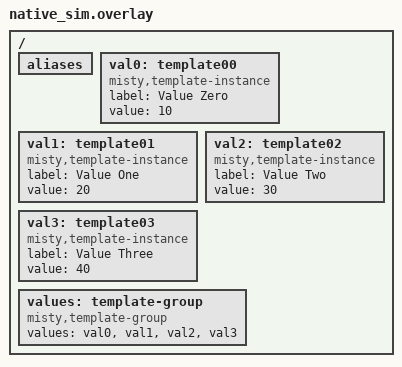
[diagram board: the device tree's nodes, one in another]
/**
 * @file native_sim.overlay
 * @date 20250526
 * @author flynnty
 * @copyright flynnty 2025
 *
 * @brief
 * Sim Overlay
 *
 */

/ {
	aliases {
	};

	val0: template00 {
		compatible = "misty,template-instance";
		#value-cells = <0>;
		label = "Value Zero";
		value = <10>;
	};

	val1: template01 {
		compatible = "misty,template-instance";
		#value-cells = <0>;
		label = "Value One";
		value = <20>;
	};

	val2: template02 {
		compatible = "misty,template-instance";
		#value-cells = <0>;
		label = "Value Two";
		value = <30>;
	};

	val3: template03 {
		compatible = "misty,template-instance";
		#value-cells = <0>;
		label = "Value Three";
		value = <40>;
	};

	values: template-group {
		compatible = "misty,template-group";
		values = <&val0 &val1 &val2 &val3>;
	};
};
